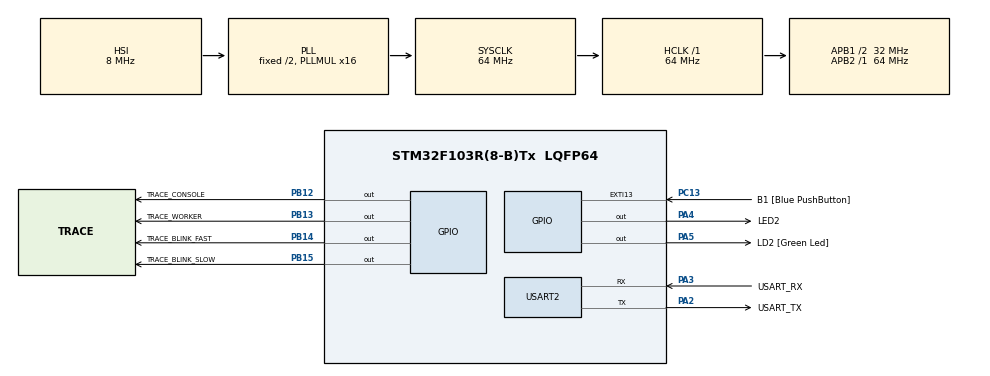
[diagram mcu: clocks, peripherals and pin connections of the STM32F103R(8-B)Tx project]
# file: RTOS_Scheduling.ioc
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FREERTOS.Tasks01=ConsoleTask,40,384,ConsoleTask_Entry,Default,NULL,Dynamic,NULL,NULL;WorkerTask,16,128,WorkerTask_Entry,Default,NULL,Dynamic,NULL,NULL;BlinkFastTask,8,128,BlinkFastTask_Entry,Default,NULL,Dynamic,NULL,NULL;BlinkSlowTask,8,128,BlinkSlowTask_Entry,Default,NULL,Dynamic,NULL,NULL
FREERTOS.configCHECK_FOR_STACK_OVERFLOW=2
FREERTOS.configGENERATE_RUN_TIME_STATS=1
FREERTOS.configTOTAL_HEAP_SIZE=6144
FREERTOS.configUSE_APPLICATION_TASK_TAG=1
FREERTOS.configUSE_MALLOC_FAILED_HOOK=1
Mcu.Family=STM32F1
Mcu.Name=STM32F103R(8-B)Tx
Mcu.Package=LQFP64
NVIC.EXTI15_10_IRQn=true\:6\:0\:false\:false\:true\:true\:true\:true\:true
NVIC.PriorityGroup=NVIC_PRIORITYGROUP_4
NVIC.TIM3_IRQn=true\:15\:0\:false\:false\:true\:false\:false\:true\:true
NVIC.TimeBase=TIM3_IRQn
NVIC.TimeBaseIP=TIM3
NVIC.USART2_IRQn=true\:6\:0\:false\:false\:true\:true\:true\:true\:true
PA13.GPIO_Label=TMS
PA13.Mode=Serial_Wire
PA13.Signal=SYS_JTMS-SWDIO
PA14.GPIO_Label=TCK
PA14.Mode=Serial_Wire
PA14.Signal=SYS_JTCK-SWCLK
PA2.GPIO_Label=USART_TX
PA2.GPIO_Mode=GPIO_MODE_AF_PP
PA2.GPIO_PuPd=GPIO_NOPULL
PA2.GPIO_Speed=GPIO_SPEED_FREQ_LOW
PA2.Mode=Asynchronous
PA2.Signal=USART2_TX
PA3.GPIO_Label=USART_RX
PA3.GPIO_Mode=GPIO_MODE_AF_PP
PA3.GPIO_PuPd=GPIO_NOPULL
PA3.GPIO_Speed=GPIO_SPEED_FREQ_LOW
PA3.Mode=Asynchronous
PA3.Signal=USART2_RX
PA4.GPIO_Label=LED2
PA4.Signal=GPIO_Output
PA5.GPIO_Label=LD2 [Green Led]
PA5.GPIO_ModeDefaultOutputPP=GPIO_MODE_OUTPUT_PP
PA5.GPIO_PuPd=GPIO_NOPULL
PA5.GPIO_Speed=GPIO_SPEED_FREQ_LOW
PA5.Signal=GPIO_Output
PB12.GPIO_Label=TRACE_CONSOLE
PB12.GPIO_Speed=GPIO_SPEED_FREQ_HIGH
PB12.Signal=GPIO_Output
PB13.GPIO_Label=TRACE_WORKER
PB13.GPIO_Speed=GPIO_SPEED_FREQ_HIGH
PB13.Signal=GPIO_Output
PB14.GPIO_Label=TRACE_BLINK_FAST
PB14.GPIO_Speed=GPIO_SPEED_FREQ_HIGH
PB14.Signal=GPIO_Output
PB15.GPIO_Label=TRACE_BLINK_SLOW
PB15.GPIO_Speed=GPIO_SPEED_FREQ_HIGH
PB15.Signal=GPIO_Output
PB3.GPIO_Label=SWO
PB3.Signal=SYS_JTDO-TRACESWO
PC13-TAMPER-RTC.GPIO_Label=B1 [Blue PushButton]
PC13-TAMPER-RTC.GPIO_ModeDefaultEXTI=GPIO_MODE_IT_FALLING
PC13-TAMPER-RTC.GPIO_PuPd=GPIO_NOPULL
PC13-TAMPER-RTC.Signal=GPXTI13
PC14-OSC32_IN.Mode=LSE-External-Oscillator
PC14-OSC32_IN.Signal=RCC_OSC32_IN
PC15-OSC32_OUT.Mode=LSE-External-Oscillator
PC15-OSC32_OUT.Signal=RCC_OSC32_OUT
PD0-OSC_IN.Mode=HSE-External-Clock-Source
PD0-OSC_IN.Signal=RCC_OSC_IN
PD1-OSC_OUT.Mode=HSE-External-Clock-Source
PD1-OSC_OUT.Signal=RCC_OSC_OUT
ProjectManager.HeapSize=0x200
ProjectManager.StackSize=0x400
ProjectManager.TargetToolchain=STM32CubeIDE
RCC.AHBFreq_Value=64000000
RCC.APB1CLKDivider=RCC_HCLK_DIV2
RCC.APB1Freq_Value=32000000
RCC.APB1TimFreq_Value=64000000
RCC.APB2Freq_Value=64000000
RCC.APB2TimFreq_Value=64000000
RCC.HCLKFreq_Value=64000000
RCC.PLLMUL=RCC_PLL_MUL16
RCC.RTCClockSelection=RCC_RTCCLKSOURCE_LSE
RCC.SYSCLKFreq_VALUE=64000000
RCC.SYSCLKSource=RCC_SYSCLKSOURCE_PLLCLK
RCC.USBFreq_Value=64000000
USART2.VirtualMode=VM_ASYNC
VP_FREERTOS_VS_CMSIS_V2.Mode=CMSIS_V2
VP_SYS_VS_tim3.Mode=TIM3
board=NUCLEO-F103RB

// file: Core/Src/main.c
/* USER CODE BEGIN Header */
/**
  ******************************************************************************
  * @file           : main.c
  * @brief          : FreeRTOS scheduling demo on NUCLEO-F103RB
  ******************************************************************************
  * Four application tasks share the CPU under the FreeRTOS fixed-priority
  * preemptive scheduler:
  *   console    (high)    serial shell, run-time statistics ("top")
  *   worker     (below)   adjustable CPU load, 100 ms period
  *   blink_fast (low)     LD2, 100 ms
  *   blink_slow (low)     external LED on PA4, 500 ms
  * Priorities, load and suspension are changed live from the terminal; every
  * context switch drives a trace pin (PB12..PB15) for a logic analyzer.
  *
  * Peripheral and RTOS objects below follow STM32CubeMX (RTOS_Scheduling.ioc);
  * application code lives in app_sched.c and USER CODE blocks.
  *
  * Author: Faizan Saleem Siddiqui (https://github.com/FaizanSSDQ)
  ******************************************************************************
  */
/* USER CODE END Header */
#include "main.h"
#include "cmsis_os.h"

/* USER CODE BEGIN Includes */
#include "app_sched.h"
/* USER CODE END Includes */

UART_HandleTypeDef huart2;

/* Definitions for ConsoleTask */
osThreadId_t ConsoleTaskHandle;
const osThreadAttr_t ConsoleTask_attributes = {
  .name = "console",
  .stack_size = 384 * 4,
  .priority = (osPriority_t) osPriorityHigh,
};
/* Definitions for WorkerTask */
osThreadId_t WorkerTaskHandle;
const osThreadAttr_t WorkerTask_attributes = {
  .name = "worker",
  .stack_size = 128 * 4,
  .priority = (osPriority_t) osPriorityBelowNormal,
};
/* Definitions for BlinkFastTask */
osThreadId_t BlinkFastTaskHandle;
const osThreadAttr_t BlinkFastTask_attributes = {
  .name = "blink_fast",
  .stack_size = 128 * 4,
  .priority = (osPriority_t) osPriorityLow,
};
/* Definitions for BlinkSlowTask */
osThreadId_t BlinkSlowTaskHandle;
const osThreadAttr_t BlinkSlowTask_attributes = {
  .name = "blink_slow",
  .stack_size = 128 * 4,
  .priority = (osPriority_t) osPriorityLow,
};

void SystemClock_Config(void);
static void MX_GPIO_Init(void);
static void MX_USART2_UART_Init(void);
void ConsoleTask_Entry(void *argument);
void WorkerTask_Entry(void *argument);
void BlinkFastTask_Entry(void *argument);
void BlinkSlowTask_Entry(void *argument);

int main(void)
{
  /* MCU Configuration--------------------------------------------------------*/

  /* Reset of all peripherals, Initializes the Flash interface and the Systick. */
  HAL_Init();

  /* Configure the system clock */
  SystemClock_Config();

  /* Initialize all configured peripherals */
  MX_GPIO_Init();
  MX_USART2_UART_Init();

  /* Init scheduler */
  osKernelInitialize();

  /* USER CODE BEGIN RTOS_QUEUES */
  app_init();
  /* USER CODE END RTOS_QUEUES */

  /* Create the thread(s) */
  /* creation of ConsoleTask */
  ConsoleTaskHandle = osThreadNew(ConsoleTask_Entry, NULL, &ConsoleTask_attributes);

  /* creation of WorkerTask */
  WorkerTaskHandle = osThreadNew(WorkerTask_Entry, NULL, &WorkerTask_attributes);

  /* creation of BlinkFastTask */
  BlinkFastTaskHandle = osThreadNew(BlinkFastTask_Entry, NULL, &BlinkFastTask_attributes);

  /* creation of BlinkSlowTask */
  BlinkSlowTaskHandle = osThreadNew(BlinkSlowTask_Entry, NULL, &BlinkSlowTask_attributes);

  /* USER CODE BEGIN RTOS_THREADS */
  app_register_tasks(ConsoleTaskHandle, WorkerTaskHandle, BlinkFastTaskHandle, BlinkSlowTaskHandle);
  /* USER CODE END RTOS_THREADS */

  /* Start scheduler */
  osKernelStart();

  /* We should never get here as control is now taken by the scheduler */
  /* Infinite loop */
  while (1)
  {

  }
}

void SystemClock_Config(void)
{
  RCC_OscInitTypeDef RCC_OscInitStruct = {0};
  RCC_ClkInitTypeDef RCC_ClkInitStruct = {0};

  /** Initializes the RCC Oscillators according to the specified parameters
  * in the RCC_OscInitTypeDef structure.
  */
  RCC_OscInitStruct.OscillatorType = RCC_OSCILLATORTYPE_HSI;
  RCC_OscInitStruct.HSIState = RCC_HSI_ON;
  RCC_OscInitStruct.HSICalibrationValue = RCC_HSICALIBRATION_DEFAULT;
  RCC_OscInitStruct.PLL.PLLState = RCC_PLL_ON;
  RCC_OscInitStruct.PLL.PLLSource = RCC_PLLSOURCE_HSI_DIV2;
  RCC_OscInitStruct.PLL.PLLMUL = RCC_PLL_MUL16;
  if (HAL_RCC_OscConfig(&RCC_OscInitStruct) != HAL_OK)
  {
    Error_Handler();
  }

  /** Initializes the CPU, AHB and APB buses clocks
  */
  RCC_ClkInitStruct.ClockType = RCC_CLOCKTYPE_HCLK|RCC_CLOCKTYPE_SYSCLK
                              |RCC_CLOCKTYPE_PCLK1|RCC_CLOCKTYPE_PCLK2;
  RCC_ClkInitStruct.SYSCLKSource = RCC_SYSCLKSOURCE_PLLCLK;
  RCC_ClkInitStruct.AHBCLKDivider = RCC_SYSCLK_DIV1;
  RCC_ClkInitStruct.APB1CLKDivider = RCC_HCLK_DIV2;
  RCC_ClkInitStruct.APB2CLKDivider = RCC_HCLK_DIV1;

  if (HAL_RCC_ClockConfig(&RCC_ClkInitStruct, FLASH_LATENCY_2) != HAL_OK)
  {
    Error_Handler();
  }
}

static void MX_USART2_UART_Init(void)
{
  huart2.Instance = USART2;
  huart2.Init.BaudRate = 115200;
  huart2.Init.WordLength = UART_WORDLENGTH_8B;
  huart2.Init.StopBits = UART_STOPBITS_1;
  huart2.Init.Parity = UART_PARITY_NONE;
  huart2.Init.Mode = UART_MODE_TX_RX;
  huart2.Init.HwFlowCtl = UART_HWCONTROL_NONE;
  huart2.Init.OverSampling = UART_OVERSAMPLING_16;
  if (HAL_UART_Init(&huart2) != HAL_OK)
  {
    Error_Handler();
  }
}

static void MX_GPIO_Init(void)
{
  GPIO_InitTypeDef GPIO_InitStruct = {0};

  /* GPIO Ports Clock Enable */
  __HAL_RCC_GPIOC_CLK_ENABLE();
  __HAL_RCC_GPIOD_CLK_ENABLE();
  __HAL_RCC_GPIOA_CLK_ENABLE();
  __HAL_RCC_GPIOB_CLK_ENABLE();

  /*Configure GPIO pin Output Level */
  HAL_GPIO_WritePin(GPIOA, LED2_Pin|LD2_Pin, GPIO_PIN_RESET);

  /*Configure GPIO pin Output Level */
  HAL_GPIO_WritePin(GPIOB, TRACE_CONSOLE_Pin|TRACE_WORKER_Pin|TRACE_BLINK_FAST_Pin|TRACE_BLINK_SLOW_Pin, GPIO_PIN_RESET);

  /*Configure GPIO pin : B1_Pin (pressed = low) */
  GPIO_InitStruct.Pin = B1_Pin;
  GPIO_InitStruct.Mode = GPIO_MODE_IT_FALLING;
  GPIO_InitStruct.Pull = GPIO_NOPULL;
  HAL_GPIO_Init(B1_GPIO_Port, &GPIO_InitStruct);

  /*Configure GPIO pins : LED2_Pin LD2_Pin */
  GPIO_InitStruct.Pin = LED2_Pin|LD2_Pin;
  GPIO_InitStruct.Mode = GPIO_MODE_OUTPUT_PP;
  GPIO_InitStruct.Pull = GPIO_NOPULL;
  GPIO_InitStruct.Speed = GPIO_SPEED_FREQ_LOW;
  HAL_GPIO_Init(GPIOA, &GPIO_InitStruct);

  /*Configure GPIO pins : TRACE_CONSOLE_Pin TRACE_WORKER_Pin TRACE_BLINK_FAST_Pin TRACE_BLINK_SLOW_Pin */
  GPIO_InitStruct.Pin = TRACE_CONSOLE_Pin|TRACE_WORKER_Pin|TRACE_BLINK_FAST_Pin|TRACE_BLINK_SLOW_Pin;
  GPIO_InitStruct.Mode = GPIO_MODE_OUTPUT_PP;
  GPIO_InitStruct.Pull = GPIO_NOPULL;
  GPIO_InitStruct.Speed = GPIO_SPEED_FREQ_HIGH;
  HAL_GPIO_Init(GPIOB, &GPIO_InitStruct);

  /* EXTI interrupt init (priority 6: may call FreeRTOS ISR API) */
  HAL_NVIC_SetPriority(EXTI15_10_IRQn, 6, 0);
  HAL_NVIC_EnableIRQ(EXTI15_10_IRQn);
}

void ConsoleTask_Entry(void *argument)
{
  /* USER CODE BEGIN ConsoleTask_Entry */
  app_console_task(argument);
  /* USER CODE END ConsoleTask_Entry */
}

void WorkerTask_Entry(void *argument)
{
  /* USER CODE BEGIN WorkerTask_Entry */
  app_worker_task(argument);
  /* USER CODE END WorkerTask_Entry */
}

void BlinkFastTask_Entry(void *argument)
{
  /* USER CODE BEGIN BlinkFastTask_Entry */
  app_blink_task(argument, LD2_GPIO_Port, LD2_Pin, 100u);
  /* USER CODE END BlinkFastTask_Entry */
}

void BlinkSlowTask_Entry(void *argument)
{
  /* USER CODE BEGIN BlinkSlowTask_Entry */
  app_blink_task(argument, LED2_GPIO_Port, LED2_Pin, 500u);
  /* USER CODE END BlinkSlowTask_Entry */
}

void HAL_TIM_PeriodElapsedCallback(TIM_HandleTypeDef *htim)
{
  if (htim->Instance == TIM3) {
    HAL_IncTick();
  }
}

void Error_Handler(void)
{
  __disable_irq();
  while (1)
  {
  }
}

#ifdef  USE_FULL_ASSERT
/**
  * @brief  Reports the name of the source file and the source line number
  *         where the assert_param error has occurred.
  * @param  file: pointer to the source file name
  * @param  line: assert_param error line source number
  * @retval None
  */
void assert_failed(uint8_t *file, uint32_t line)
{
  /* USER CODE BEGIN 6 */
  (void)file;
  (void)line;
  /* USER CODE END 6 */
}
#endif /* USE_FULL_ASSERT */
